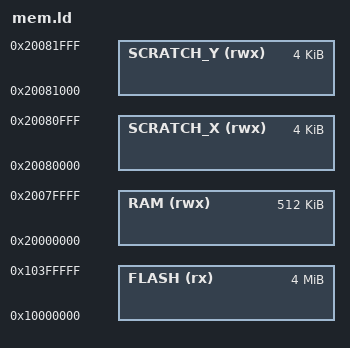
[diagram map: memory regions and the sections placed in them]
/*
 * DO NOT EDIT! Automatically generated from template file:
 * build-helper/templates/common/_micro-os-plus/tests/platforms/raspberry-pi-pico-2-riscv/linker-scripts/mem-liquid.ld
 *
 * The Raspberry Pi Pico 2 memory map.
 * The memory sections are defined in the `startup` package.
 */
MEMORY
{
    FLASH(rx) : ORIGIN = 0x10000000, LENGTH = 4096k
    RAM(rwx) : ORIGIN =  0x20000000, LENGTH = 512k
    SCRATCH_X(rwx) : ORIGIN = 0x20080000, LENGTH = 4k
    SCRATCH_Y(rwx) : ORIGIN = 0x20081000, LENGTH = 4k
}
